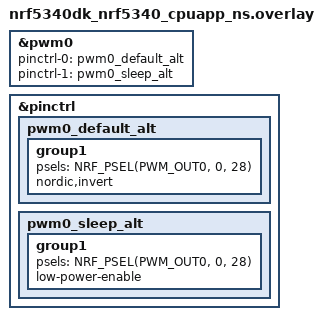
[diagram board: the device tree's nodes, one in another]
&pwm0 {
	status = "okay";
	pinctrl-0 = <&pwm0_default_alt>;
	pinctrl-1 = <&pwm0_sleep_alt>;
	pinctrl-names = "default", "sleep";
};

&pinctrl {
	pwm0_default_alt: pwm0_default_alt {
		group1 {
			psels = <NRF_PSEL(PWM_OUT0, 0, 28)>;
			nordic,invert;
		};
	};

	pwm0_sleep_alt: pwm0_sleep_alt {
		group1 {
			psels = <NRF_PSEL(PWM_OUT0, 0, 28)>;
			low-power-enable;
		};
	};
};
